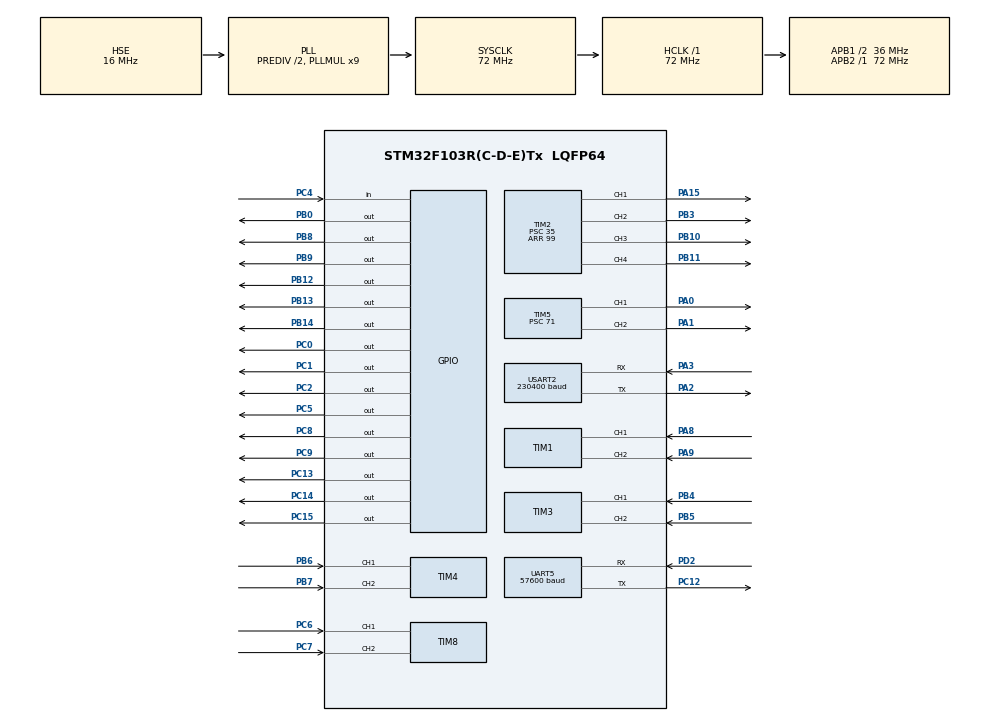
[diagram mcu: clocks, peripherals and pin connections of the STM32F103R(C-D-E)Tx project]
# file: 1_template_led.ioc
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Dma.Request0=USART2_RX
Dma.Request1=USART2_TX
Dma.USART2_RX.0.Direction=DMA_PERIPH_TO_MEMORY
Dma.USART2_RX.0.Instance=DMA1_Channel6
Dma.USART2_RX.0.MemDataAlignment=DMA_MDATAALIGN_BYTE
Dma.USART2_RX.0.MemInc=DMA_MINC_ENABLE
Dma.USART2_RX.0.Mode=DMA_CIRCULAR
Dma.USART2_RX.0.PeriphDataAlignment=DMA_PDATAALIGN_BYTE
Dma.USART2_RX.0.PeriphInc=DMA_PINC_DISABLE
Dma.USART2_RX.0.Priority=DMA_PRIORITY_HIGH
Dma.USART2_TX.1.Direction=DMA_MEMORY_TO_PERIPH
Dma.USART2_TX.1.Instance=DMA1_Channel7
Dma.USART2_TX.1.MemDataAlignment=DMA_MDATAALIGN_BYTE
Dma.USART2_TX.1.MemInc=DMA_MINC_ENABLE
Dma.USART2_TX.1.Mode=DMA_NORMAL
Dma.USART2_TX.1.PeriphDataAlignment=DMA_PDATAALIGN_BYTE
Dma.USART2_TX.1.PeriphInc=DMA_PINC_DISABLE
Dma.USART2_TX.1.Priority=DMA_PRIORITY_MEDIUM
FREERTOS.INCLUDE_vTaskDelayUntil=1
FREERTOS.Tasks01=defaultTask,0,128,StartDefaultTask,Default,NULL,Dynamic,NULL,NULL
FREERTOS.configTOTAL_HEAP_SIZE=12288
Mcu.Family=STM32F1
Mcu.Name=STM32F103R(C-D-E)Tx
Mcu.Package=LQFP64
NVIC.DMA1_Channel6_IRQn=true\:5\:0\:false\:false\:true\:true\:false\:true\:true
NVIC.DMA1_Channel7_IRQn=true\:5\:0\:false\:false\:true\:true\:false\:true\:true
NVIC.PriorityGroup=NVIC_PRIORITYGROUP_4
NVIC.TIM5_IRQn=true\:4\:0\:true\:false\:true\:true\:true\:true\:true
NVIC.TIM6_IRQn=true\:5\:0\:true\:false\:true\:true\:true\:true\:true
NVIC.UART5_IRQn=true\:5\:0\:true\:false\:true\:true\:true\:true\:true
NVIC.USART2_IRQn=true\:5\:0\:true\:false\:true\:true\:true\:true\:true
PA13.Mode=Serial_Wire
PA13.Signal=SYS_JTMS-SWDIO
PA14.Mode=Serial_Wire
PA14.Signal=SYS_JTCK-SWCLK
PA15.Signal=S_TIM2_CH1_ETR
PA0-WKUP.Signal=S_TIM5_CH1
PA1.Signal=S_TIM5_CH2
PA2.Mode=Asynchronous
PA2.Signal=USART2_TX
PA3.Mode=Asynchronous
PA3.Signal=USART2_RX
PA8.Signal=S_TIM1_CH1
PA9.Signal=S_TIM1_CH2
PB10.Signal=S_TIM2_CH3
PB11.Signal=S_TIM2_CH4
PB12.Signal=GPIO_Output
PB13.Signal=GPIO_Output
PB14.Signal=GPIO_Output
PB0.Signal=GPIO_Output
PB3.Signal=S_TIM2_CH2
PB4.Signal=S_TIM3_CH1
PB5.Signal=S_TIM3_CH2
PB6.Signal=S_TIM4_CH1
PB7.Signal=S_TIM4_CH2
PB8.GPIO_ModeDefaultOutputPP=GPIO_MODE_OUTPUT_OD
PB8.GPIO_PuPd=GPIO_NOPULL
PB8.Signal=GPIO_Output
PB9.GPIO_ModeDefaultOutputPP=GPIO_MODE_OUTPUT_OD
PB9.GPIO_PuPd=GPIO_NOPULL
PB9.Signal=GPIO_Output
PC0.Signal=GPIO_Output
PC1.Signal=GPIO_Output
PC12.Mode=Asynchronous
PC12.Signal=UART5_TX
PC13-TAMPER-RTC.Signal=GPIO_Output
PC14-OSC32_IN.Signal=GPIO_Output
PC15-OSC32_OUT.Signal=GPIO_Output
PC2.Signal=GPIO_Output
PC4.GPIO_PuPd=GPIO_PULLUP
PC4.Signal=GPIO_Input
PC5.Signal=GPIO_Output
PC6.Signal=S_TIM8_CH1
PC7.Signal=S_TIM8_CH2
PC8.Signal=GPIO_Output
PC9.Signal=GPIO_Output
PD0-OSC_IN.Mode=HSE-External-Oscillator
PD0-OSC_IN.Signal=RCC_OSC_IN
PD1-OSC_OUT.Mode=HSE-External-Oscillator
PD1-OSC_OUT.Signal=RCC_OSC_OUT
PD2.Mode=Asynchronous
PD2.Signal=UART5_RX
ProjectManager.HeapSize=0x200
ProjectManager.StackSize=0x400
ProjectManager.TargetToolchain=MDK-ARM V5.32
RCC.AHBFreq_Value=72000000
RCC.APB1CLKDivider=RCC_HCLK_DIV2
RCC.APB1Freq_Value=36000000
RCC.APB1TimFreq_Value=72000000
RCC.APB2Freq_Value=72000000
RCC.APB2TimFreq_Value=72000000
RCC.HCLKFreq_Value=72000000
RCC.HSEDivPLL=RCC_HSE_PREDIV_DIV2
RCC.HSE_VALUE=16000000
RCC.PLLMUL=RCC_PLL_MUL9
RCC.PLLSourceVirtual=RCC_PLLSOURCE_HSE
RCC.SYSCLKFreq_VALUE=72000000
RCC.SYSCLKSource=RCC_SYSCLKSOURCE_PLLCLK
RCC.USBFreq_Value=72000000
SH.S_TIM1_CH1.0=TIM1_CH1,Encoder_Interface
SH.S_TIM1_CH2.0=TIM1_CH2,Encoder_Interface
SH.S_TIM2_CH1_ETR.0=TIM2_CH1,PWM Generation1 CH1
SH.S_TIM2_CH2.0=TIM2_CH2,PWM Generation2 CH2
SH.S_TIM2_CH3.0=TIM2_CH3,PWM Generation3 CH3
SH.S_TIM2_CH4.0=TIM2_CH4,PWM Generation4 CH4
SH.S_TIM3_CH1.0=TIM3_CH1,Encoder_Interface
SH.S_TIM3_CH2.0=TIM3_CH2,Encoder_Interface
SH.S_TIM4_CH1.0=TIM4_CH1,Encoder_Interface
SH.S_TIM4_CH2.0=TIM4_CH2,Encoder_Interface
SH.S_TIM5_CH1.0=TIM5_CH1,PWM Generation1 CH1
SH.S_TIM5_CH2.0=TIM5_CH2,PWM Generation2 CH2
SH.S_TIM8_CH1.0=TIM8_CH1,Encoder_Interface
SH.S_TIM8_CH2.0=TIM8_CH2,Encoder_Interface
TIM1.EncoderMode=TIM_ENCODERMODE_TI12
TIM2.Channel-PWM\ Generation1\ CH1=TIM_CHANNEL_1
TIM2.Channel-PWM\ Generation2\ CH2=TIM_CHANNEL_2
TIM2.Channel-PWM\ Generation3\ CH3=TIM_CHANNEL_3
TIM2.Channel-PWM\ Generation4\ CH4=TIM_CHANNEL_4
TIM2.Period=99
TIM2.Prescaler=35
TIM3.EncoderMode=TIM_ENCODERMODE_TI12
TIM4.EncoderMode=TIM_ENCODERMODE_TI12
TIM5.Channel-PWM\ Generation1\ CH1=TIM_CHANNEL_1
TIM5.Channel-PWM\ Generation2\ CH2=TIM_CHANNEL_2
TIM5.Period=19999
TIM5.Prescaler=71
TIM6.Period=199
TIM6.Prescaler=7199
TIM8.EncoderMode=TIM_ENCODERMODE_TI12
UART5.BaudRate=57600
UART5.VirtualMode=Asynchronous
USART2.BaudRate=230400
USART2.VirtualMode=VM_ASYNC
VP_FREERTOS_VS_CMSIS_V1.Mode=CMSIS_V1
VP_TIM2_VS_ClockSourceINT.Mode=Internal
VP_TIM5_VS_ClockSourceINT.Mode=Internal
VP_TIM6_VS_ClockSourceINT.Mode=Enable_Timer
board=custom

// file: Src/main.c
/* USER CODE BEGIN Header */
/**
  ******************************************************************************
  * @file           : main.c
  * @brief          : Main program body
  ******************************************************************************
  * @attention
  *
  * Copyright (c) 2026 STMicroelectronics.
  * All rights reserved.
  *
  * This software is licensed under terms that can be found in the LICENSE file
  * in the root directory of this software component.
  * If no LICENSE file comes with this software, it is provided AS-IS.
  *
  ******************************************************************************
  */
/* USER CODE END Header */
#include "main.h"
#include "cmsis_os.h"
#include "dma.h"
#include "tim.h"
#include "usart.h"
#include "gpio.h"

void SystemClock_Config(void);
void MX_FREERTOS_Init(void);

int main(void)
{

  /* MCU Configuration--------------------------------------------------------*/

  /* Reset of all peripherals, Initializes the Flash interface and the Systick. */
  HAL_Init();

  /* Configure the system clock */
  SystemClock_Config();

  /* Initialize all configured peripherals */
  MX_GPIO_Init();
  MX_DMA_Init();
  MX_UART5_Init();
  MX_USART2_UART_Init();
  MX_TIM2_Init();
  MX_TIM3_Init();
  MX_TIM8_Init();
  MX_TIM6_Init();
  MX_TIM1_Init();
  MX_TIM4_Init();
  MX_TIM5_Init();

  /* Call init function for freertos objects (in cmsis_os2.c) */
  MX_FREERTOS_Init();

  /* Start scheduler */
  osKernelStart();

  /* We should never get here as control is now taken by the scheduler */

  /* Infinite loop */
  while (1)
  {

	}
}

void SystemClock_Config(void)
{
  RCC_OscInitTypeDef RCC_OscInitStruct = {0};
  RCC_ClkInitTypeDef RCC_ClkInitStruct = {0};

  /** Initializes the RCC Oscillators according to the specified parameters
  * in the RCC_OscInitTypeDef structure.
  */
  RCC_OscInitStruct.OscillatorType = RCC_OSCILLATORTYPE_HSE;
  RCC_OscInitStruct.HSEState = RCC_HSE_ON;
  RCC_OscInitStruct.HSEPredivValue = RCC_HSE_PREDIV_DIV2;
  RCC_OscInitStruct.HSIState = RCC_HSI_ON;
  RCC_OscInitStruct.PLL.PLLState = RCC_PLL_ON;
  RCC_OscInitStruct.PLL.PLLSource = RCC_PLLSOURCE_HSE;
  RCC_OscInitStruct.PLL.PLLMUL = RCC_PLL_MUL9;
  if (HAL_RCC_OscConfig(&RCC_OscInitStruct) != HAL_OK)
  {
    Error_Handler();
  }

  /** Initializes the CPU, AHB and APB buses clocks
  */
  RCC_ClkInitStruct.ClockType = RCC_CLOCKTYPE_HCLK|RCC_CLOCKTYPE_SYSCLK
                              |RCC_CLOCKTYPE_PCLK1|RCC_CLOCKTYPE_PCLK2;
  RCC_ClkInitStruct.SYSCLKSource = RCC_SYSCLKSOURCE_PLLCLK;
  RCC_ClkInitStruct.AHBCLKDivider = RCC_SYSCLK_DIV1;
  RCC_ClkInitStruct.APB1CLKDivider = RCC_HCLK_DIV2;
  RCC_ClkInitStruct.APB2CLKDivider = RCC_HCLK_DIV1;

  if (HAL_RCC_ClockConfig(&RCC_ClkInitStruct, FLASH_LATENCY_2) != HAL_OK)
  {
    Error_Handler();
  }
}

void Error_Handler(void)
{
  __disable_irq();
  while (1)
  {
  }
}

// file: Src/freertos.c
/* USER CODE BEGIN Header */
/**
  ******************************************************************************
  * File Name          : freertos.c
  * Description        : Code for freertos applications
  ******************************************************************************
  * @attention
  *
  * Copyright (c) 2026 STMicroelectronics.
  * All rights reserved.
  *
  * This software is licensed under terms that can be found in the LICENSE file
  * in the root directory of this software component.
  * If no LICENSE file comes with this software, it is provided AS-IS.
  *
  ******************************************************************************
  */
/* USER CODE END Header */

#include "FreeRTOS.h"
#include "task.h"
#include "main.h"
#include "cmsis_os.h"

/* USER CODE BEGIN Includes */
#include "chassis_task.h"
/* USER CODE END Includes */

/* USER CODE BEGIN Variables */
osThreadId chassisTaskHandle;

/* USER CODE END Variables */
osThreadId defaultTaskHandle;

void StartDefaultTask(void const * argument);

void MX_FREERTOS_Init(void); /* (MISRA C 2004 rule 8.1) */

/* GetIdleTaskMemory prototype (linked to static allocation support) */
void vApplicationGetIdleTaskMemory( StaticTask_t **ppxIdleTaskTCBBuffer, StackType_t **ppxIdleTaskStackBuffer, uint32_t *pulIdleTaskStackSize );

/* USER CODE BEGIN GET_IDLE_TASK_MEMORY */
static StaticTask_t xIdleTaskTCBBuffer;
static StackType_t xIdleStack[configMINIMAL_STACK_SIZE];

void vApplicationGetIdleTaskMemory( StaticTask_t **ppxIdleTaskTCBBuffer, StackType_t **ppxIdleTaskStackBuffer, uint32_t *pulIdleTaskStackSize )
{
  *ppxIdleTaskTCBBuffer = &xIdleTaskTCBBuffer;
  *ppxIdleTaskStackBuffer = &xIdleStack[0];
  *pulIdleTaskStackSize = configMINIMAL_STACK_SIZE;
  /* place for user code */
}
/* USER CODE END GET_IDLE_TASK_MEMORY */

void MX_FREERTOS_Init(void) {

  /* Create the thread(s) */
  /* definition and creation of defaultTask */
  osThreadDef(defaultTask, StartDefaultTask, osPriorityNormal, 0, 128);
  defaultTaskHandle = osThreadCreate(osThread(defaultTask), NULL);

  /* USER CODE BEGIN RTOS_THREADS */
  /* add threads, ... */
	osThreadDef(chassisTask, chassis_task, osPriorityHigh, 0, 1024);
  chassisTaskHandle = osThreadCreate(osThread(chassisTask), NULL);
  /* USER CODE END RTOS_THREADS */

}

void StartDefaultTask(void const * argument)
{
  for(;;)
  {
    osDelay(1);
  }
}
